AUTOSAR XML (schema 4-0-3)
standard types defined: Boolean, UInt16, UInt8
package /AUTOSAR_Platform/DataConstrs
  range DC_Boolean: raw 0..1
  range DC_UInt16: raw 0..65535
  range DC_UInt8: raw 0..255
package /PATAC/MSM/ComponentTypes
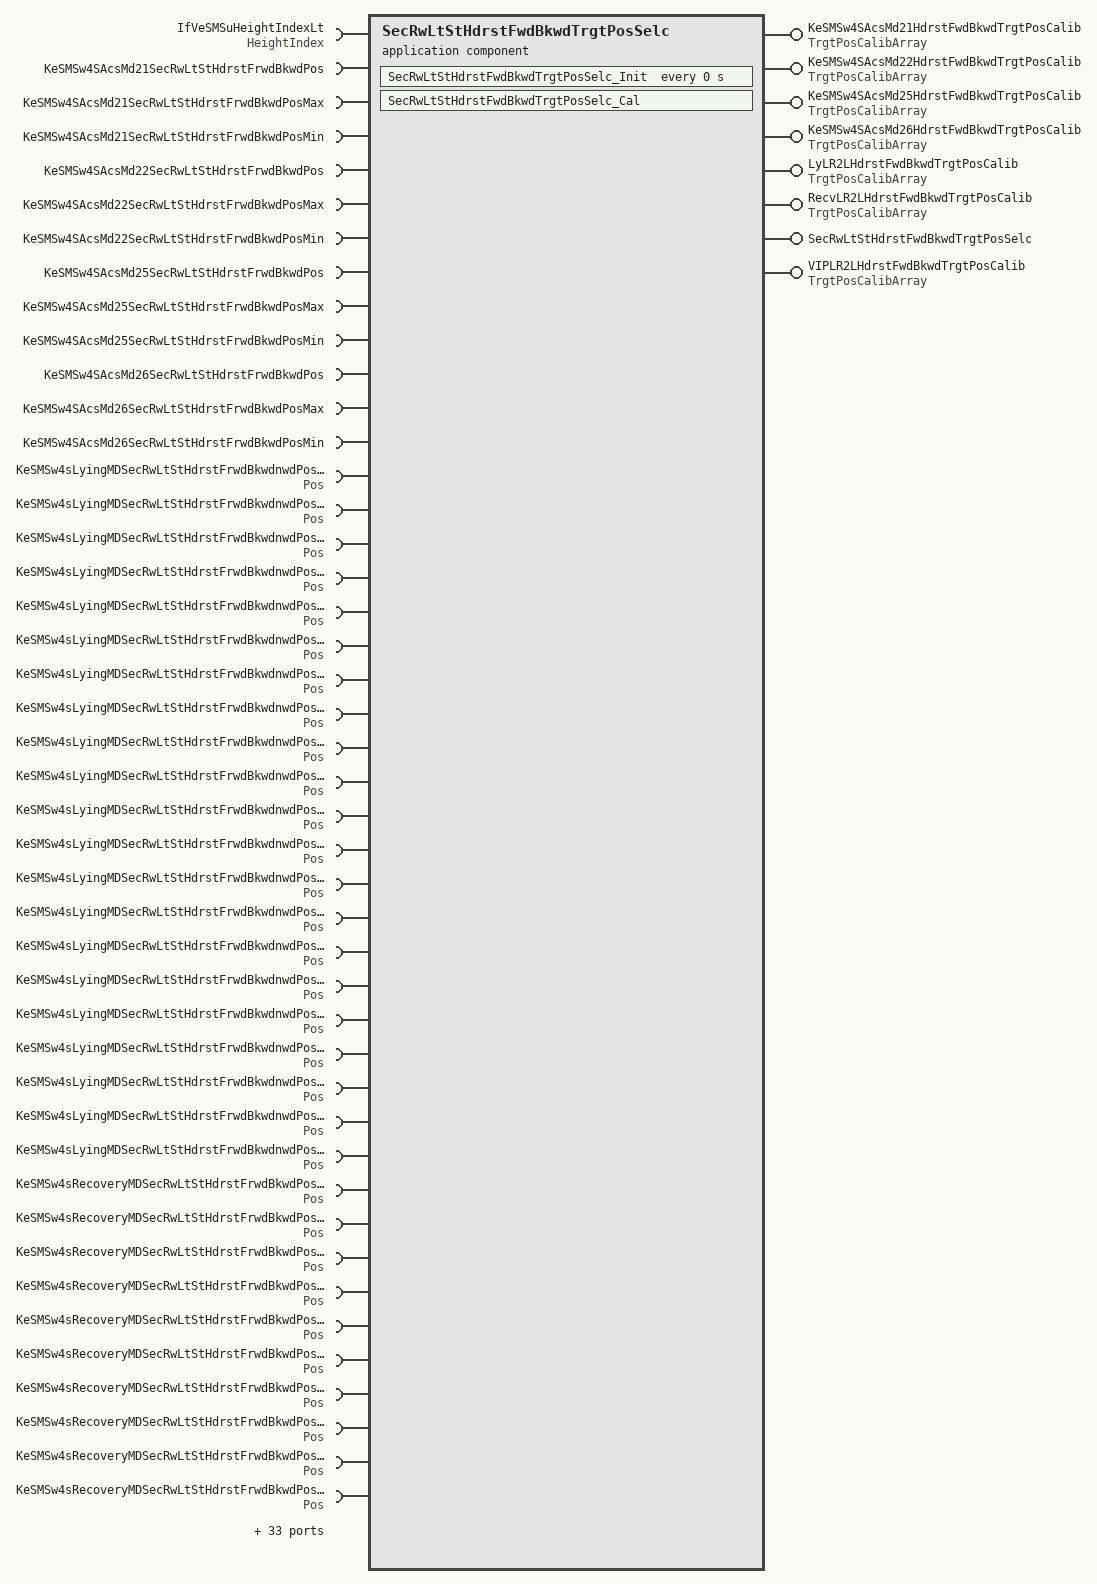
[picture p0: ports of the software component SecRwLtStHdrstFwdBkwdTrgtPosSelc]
  application sw component type SecRwLtStHdrstFwdBkwdTrgtPosSelc
    8 x provide port:
      KeSMSw4SAcsMd21HdrstFwdBkwdTrgtPosCalib: nonqueued-sender-com-spec{data-element=TrgtPosArray, init-value=[4095, 4095, 4095]}, provided-interface=TrgtPosCalibArray
      KeSMSw4SAcsMd22HdrstFwdBkwdTrgtPosCalib: nonqueued-sender-com-spec{data-element=TrgtPosArray, init-value=[4095, 4095, 4095]}, provided-interface=TrgtPosCalibArray
      KeSMSw4SAcsMd25HdrstFwdBkwdTrgtPosCalib: nonqueued-sender-com-spec{data-element=TrgtPosArray, init-value=[4095, 4095, 4095]}, provided-interface=TrgtPosCalibArray
      KeSMSw4SAcsMd26HdrstFwdBkwdTrgtPosCalib: nonqueued-sender-com-spec{data-element=TrgtPosArray, init-value=[4095, 4095, 4095]}, provided-interface=TrgtPosCalibArray
      LyLR2LHdrstFwdBkwdTrgtPosCalib: nonqueued-sender-com-spec{data-element=TrgtPosArray, init-value=[4095, 4095, 4095]}, provided-interface=TrgtPosCalibArray
      RecvLR2LHdrstFwdBkwdTrgtPosCalib: nonqueued-sender-com-spec{data-element=TrgtPosArray, init-value=[4095, 4095, 4095]}, provided-interface=TrgtPosCalibArray
      SecRwLtStHdrstFwdBkwdTrgtPosSelc: server-com-spec{operation=Cal, queue-length=1}, provided-interface=SecRwLtStHdrstFwdBkwdTrgtPosSelc
      VIPLR2LHdrstFwdBkwdTrgtPosCalib: nonqueued-sender-com-spec{data-element=TrgtPosArray, init-value=[4095, 4095, 4095]}, provided-interface=TrgtPosCalibArray
    77 x require port:
      IfVeSMSuHeightIndexLt: nonqueued-receiver-com-spec{data-element=Val, filter=data-filter-type=ALWAYS, init-value=0}, required-interface=HeightIndex
      KeSMSw4SAcsMd21SecRwLtStHdrstFrwdBkwdPos: parameter-require-com-spec{init-value=0, parameter=KeSMSw4SAcsMd21SecRwLtStHdrstFrwdBkwdPos/Val}, required-interface=KeSMSw4SAcsMd21SecRwLtStHdrstFrwdBkwdPos
      KeSMSw4SAcsMd21SecRwLtStHdrstFrwdBkwdPosMax: parameter-require-com-spec{init-value=0, parameter=KeSMSw4SAcsMd21SecRwLtStHdrstFrwdBkwdPosMax/Val}, required-interface=KeSMSw4SAcsMd21SecRwLtStHdrstFrwdBkwdPosMax
      KeSMSw4SAcsMd21SecRwLtStHdrstFrwdBkwdPosMin: parameter-require-com-spec{init-value=0, parameter=KeSMSw4SAcsMd21SecRwLtStHdrstFrwdBkwdPosMin/Val}, required-interface=KeSMSw4SAcsMd21SecRwLtStHdrstFrwdBkwdPosMin
      KeSMSw4SAcsMd22SecRwLtStHdrstFrwdBkwdPos: parameter-require-com-spec{init-value=0, parameter=KeSMSw4SAcsMd22SecRwLtStHdrstFrwdBkwdPos/Val}, required-interface=KeSMSw4SAcsMd22SecRwLtStHdrstFrwdBkwdPos
      KeSMSw4SAcsMd22SecRwLtStHdrstFrwdBkwdPosMax: parameter-require-com-spec{init-value=0, parameter=KeSMSw4SAcsMd22SecRwLtStHdrstFrwdBkwdPosMax/Val}, required-interface=KeSMSw4SAcsMd22SecRwLtStHdrstFrwdBkwdPosMax
      KeSMSw4SAcsMd22SecRwLtStHdrstFrwdBkwdPosMin: parameter-require-com-spec{init-value=0, parameter=KeSMSw4SAcsMd22SecRwLtStHdrstFrwdBkwdPosMin/Val}, required-interface=KeSMSw4SAcsMd22SecRwLtStHdrstFrwdBkwdPosMin
      KeSMSw4SAcsMd25SecRwLtStHdrstFrwdBkwdPos: parameter-require-com-spec{init-value=0, parameter=KeSMSw4SAcsMd25SecRwLtStHdrstFrwdBkwdPos/Val}, required-interface=KeSMSw4SAcsMd25SecRwLtStHdrstFrwdBkwdPos
      KeSMSw4SAcsMd25SecRwLtStHdrstFrwdBkwdPosMax: parameter-require-com-spec{init-value=0, parameter=KeSMSw4SAcsMd25SecRwLtStHdrstFrwdBkwdPosMax/Val}, required-interface=KeSMSw4SAcsMd25SecRwLtStHdrstFrwdBkwdPosMax
      KeSMSw4SAcsMd25SecRwLtStHdrstFrwdBkwdPosMin: parameter-require-com-spec{init-value=0, parameter=KeSMSw4SAcsMd25SecRwLtStHdrstFrwdBkwdPosMin/Val}, required-interface=KeSMSw4SAcsMd25SecRwLtStHdrstFrwdBkwdPosMin
      KeSMSw4SAcsMd26SecRwLtStHdrstFrwdBkwdPos: parameter-require-com-spec{init-value=0, parameter=KeSMSw4SAcsMd26SecRwLtStHdrstFrwdBkwdPos/Val}, required-interface=KeSMSw4SAcsMd26SecRwLtStHdrstFrwdBkwdPos
      KeSMSw4SAcsMd26SecRwLtStHdrstFrwdBkwdPosMax: parameter-require-com-spec{init-value=0, parameter=KeSMSw4SAcsMd26SecRwLtStHdrstFrwdBkwdPosMax/Val}, required-interface=KeSMSw4SAcsMd26SecRwLtStHdrstFrwdBkwdPosMax
      KeSMSw4SAcsMd26SecRwLtStHdrstFrwdBkwdPosMin: parameter-require-com-spec{init-value=0, parameter=KeSMSw4SAcsMd26SecRwLtStHdrstFrwdBkwdPosMin/Val}, required-interface=KeSMSw4SAcsMd26SecRwLtStHdrstFrwdBkwdPosMin
      KeSMSw4sLyingMDSecRwLtStHdrstFrwdBkwdnwdPos_160: parameter-require-com-spec{init-value=0, parameter=Pos/Val}, required-interface=Pos
      KeSMSw4sLyingMDSecRwLtStHdrstFrwdBkwdnwdPos_165: parameter-require-com-spec{init-value=0, parameter=Pos/Val}, required-interface=Pos
      KeSMSw4sLyingMDSecRwLtStHdrstFrwdBkwdnwdPos_170: parameter-require-com-spec{init-value=0, parameter=Pos/Val}, required-interface=Pos
      KeSMSw4sLyingMDSecRwLtStHdrstFrwdBkwdnwdPos_175: parameter-require-com-spec{init-value=0, parameter=Pos/Val}, required-interface=Pos
      KeSMSw4sLyingMDSecRwLtStHdrstFrwdBkwdnwdPos_180: parameter-require-com-spec{init-value=0, parameter=Pos/Val}, required-interface=Pos
      KeSMSw4sLyingMDSecRwLtStHdrstFrwdBkwdnwdPos_Below160: parameter-require-com-spec{init-value=0, parameter=Pos/Val}, required-interface=Pos
      KeSMSw4sLyingMDSecRwLtStHdrstFrwdBkwdnwdPos_Over180: parameter-require-com-spec{init-value=0, parameter=Pos/Val}, required-interface=Pos
      KeSMSw4sLyingMDSecRwLtStHdrstFrwdBkwdnwdPosMax_160: parameter-require-com-spec{init-value=0, parameter=Pos/Val}, required-interface=Pos
      KeSMSw4sLyingMDSecRwLtStHdrstFrwdBkwdnwdPosMax_165: parameter-require-com-spec{init-value=0, parameter=Pos/Val}, required-interface=Pos
      KeSMSw4sLyingMDSecRwLtStHdrstFrwdBkwdnwdPosMax_170: parameter-require-com-spec{init-value=0, parameter=Pos/Val}, required-interface=Pos
      KeSMSw4sLyingMDSecRwLtStHdrstFrwdBkwdnwdPosMax_175: parameter-require-com-spec{init-value=0, parameter=Pos/Val}, required-interface=Pos
      KeSMSw4sLyingMDSecRwLtStHdrstFrwdBkwdnwdPosMax_180: parameter-require-com-spec{init-value=0, parameter=Pos/Val}, required-interface=Pos
      KeSMSw4sLyingMDSecRwLtStHdrstFrwdBkwdnwdPosMax_Below160: parameter-require-com-spec{init-value=0, parameter=Pos/Val}, required-interface=Pos
      KeSMSw4sLyingMDSecRwLtStHdrstFrwdBkwdnwdPosMax_Over180: parameter-require-com-spec{init-value=0, parameter=Pos/Val}, required-interface=Pos
      KeSMSw4sLyingMDSecRwLtStHdrstFrwdBkwdnwdPosMin_160: parameter-require-com-spec{init-value=0, parameter=Pos/Val}, required-interface=Pos
      KeSMSw4sLyingMDSecRwLtStHdrstFrwdBkwdnwdPosMin_165: parameter-require-com-spec{init-value=0, parameter=Pos/Val}, required-interface=Pos
      KeSMSw4sLyingMDSecRwLtStHdrstFrwdBkwdnwdPosMin_170: parameter-require-com-spec{init-value=0, parameter=Pos/Val}, required-interface=Pos
      KeSMSw4sLyingMDSecRwLtStHdrstFrwdBkwdnwdPosMin_175: parameter-require-com-spec{init-value=0, parameter=Pos/Val}, required-interface=Pos
      KeSMSw4sLyingMDSecRwLtStHdrstFrwdBkwdnwdPosMin_180: parameter-require-com-spec{init-value=0, parameter=Pos/Val}, required-interface=Pos
      KeSMSw4sLyingMDSecRwLtStHdrstFrwdBkwdnwdPosMin_Below160: parameter-require-com-spec{init-value=0, parameter=Pos/Val}, required-interface=Pos
      KeSMSw4sLyingMDSecRwLtStHdrstFrwdBkwdnwdPosMin_Over180: parameter-require-com-spec{init-value=0, parameter=Pos/Val}, required-interface=Pos
      KeSMSw4sRecoveryMDSecRwLtStHdrstFrwdBkwdPos_160: parameter-require-com-spec{init-value=0, parameter=Pos/Val}, required-interface=Pos
      KeSMSw4sRecoveryMDSecRwLtStHdrstFrwdBkwdPos_165: parameter-require-com-spec{init-value=0, parameter=Pos/Val}, required-interface=Pos
      KeSMSw4sRecoveryMDSecRwLtStHdrstFrwdBkwdPos_170: parameter-require-com-spec{init-value=0, parameter=Pos/Val}, required-interface=Pos
      KeSMSw4sRecoveryMDSecRwLtStHdrstFrwdBkwdPos_175: parameter-require-com-spec{init-value=0, parameter=Pos/Val}, required-interface=Pos
      KeSMSw4sRecoveryMDSecRwLtStHdrstFrwdBkwdPos_180: parameter-require-com-spec{init-value=0, parameter=Pos/Val}, required-interface=Pos
      KeSMSw4sRecoveryMDSecRwLtStHdrstFrwdBkwdPos_Below160: parameter-require-com-spec{init-value=0, parameter=Pos/Val}, required-interface=Pos
      KeSMSw4sRecoveryMDSecRwLtStHdrstFrwdBkwdPos_Over180: parameter-require-com-spec{init-value=0, parameter=Pos/Val}, required-interface=Pos
      KeSMSw4sRecoveryMDSecRwLtStHdrstFrwdBkwdPosMax_160: parameter-require-com-spec{init-value=0, parameter=Pos/Val}, required-interface=Pos
      KeSMSw4sRecoveryMDSecRwLtStHdrstFrwdBkwdPosMax_165: parameter-require-com-spec{init-value=0, parameter=Pos/Val}, required-interface=Pos
      KeSMSw4sRecoveryMDSecRwLtStHdrstFrwdBkwdPosMax_170: parameter-require-com-spec{init-value=0, parameter=Pos/Val}, required-interface=Pos
      KeSMSw4sRecoveryMDSecRwLtStHdrstFrwdBkwdPosMax_175: parameter-require-com-spec{init-value=0, parameter=Pos/Val}, required-interface=Pos
      KeSMSw4sRecoveryMDSecRwLtStHdrstFrwdBkwdPosMax_180: parameter-require-com-spec{init-value=0, parameter=Pos/Val}, required-interface=Pos
      KeSMSw4sRecoveryMDSecRwLtStHdrstFrwdBkwdPosMax_Below160: parameter-require-com-spec{init-value=0, parameter=Pos/Val}, required-interface=Pos
      KeSMSw4sRecoveryMDSecRwLtStHdrstFrwdBkwdPosMax_Over180: parameter-require-com-spec{init-value=0, parameter=Pos/Val}, required-interface=Pos
      KeSMSw4sRecoveryMDSecRwLtStHdrstFrwdBkwdPosMin_160: parameter-require-com-spec{init-value=0, parameter=Pos/Val}, required-interface=Pos
      KeSMSw4sRecoveryMDSecRwLtStHdrstFrwdBkwdPosMin_165: parameter-require-com-spec{init-value=0, parameter=Pos/Val}, required-interface=Pos
      KeSMSw4sRecoveryMDSecRwLtStHdrstFrwdBkwdPosMin_170: parameter-require-com-spec{init-value=0, parameter=Pos/Val}, required-interface=Pos
      KeSMSw4sRecoveryMDSecRwLtStHdrstFrwdBkwdPosMin_175: parameter-require-com-spec{init-value=0, parameter=Pos/Val}, required-interface=Pos
      KeSMSw4sRecoveryMDSecRwLtStHdrstFrwdBkwdPosMin_180: parameter-require-com-spec{init-value=0, parameter=Pos/Val}, required-interface=Pos
      KeSMSw4sRecoveryMDSecRwLtStHdrstFrwdBkwdPosMin_Below160: parameter-require-com-spec{init-value=0, parameter=Pos/Val}, required-interface=Pos
      KeSMSw4sRecoveryMDSecRwLtStHdrstFrwdBkwdPosMin_Over180: parameter-require-com-spec{init-value=0, parameter=Pos/Val}, required-interface=Pos
      KeSMSw4sVIPMDSecRwLtStHdrstFrwdBkwdPos_160: parameter-require-com-spec{init-value=0, parameter=Pos/Val}, required-interface=Pos
      KeSMSw4sVIPMDSecRwLtStHdrstFrwdBkwdPos_165: parameter-require-com-spec{init-value=0, parameter=Pos/Val}, required-interface=Pos
      KeSMSw4sVIPMDSecRwLtStHdrstFrwdBkwdPos_170: parameter-require-com-spec{init-value=0, parameter=Pos/Val}, required-interface=Pos
      KeSMSw4sVIPMDSecRwLtStHdrstFrwdBkwdPos_175: parameter-require-com-spec{init-value=0, parameter=Pos/Val}, required-interface=Pos
      KeSMSw4sVIPMDSecRwLtStHdrstFrwdBkwdPos_180: parameter-require-com-spec{init-value=0, parameter=Pos/Val}, required-interface=Pos
      KeSMSw4sVIPMDSecRwLtStHdrstFrwdBkwdPos_Below160: parameter-require-com-spec{init-value=0, parameter=Pos/Val}, required-interface=Pos
      KeSMSw4sVIPMDSecRwLtStHdrstFrwdBkwdPos_Over180: parameter-require-com-spec{init-value=0, parameter=Pos/Val}, required-interface=Pos
      KeSMSw4sVIPMDSecRwLtStHdrstFrwdBkwdPosMax_160: parameter-require-com-spec{init-value=0, parameter=Pos/Val}, required-interface=Pos
      KeSMSw4sVIPMDSecRwLtStHdrstFrwdBkwdPosMax_165: parameter-require-com-spec{init-value=0, parameter=Pos/Val}, required-interface=Pos
      KeSMSw4sVIPMDSecRwLtStHdrstFrwdBkwdPosMax_170: parameter-require-com-spec{init-value=0, parameter=Pos/Val}, required-interface=Pos
      KeSMSw4sVIPMDSecRwLtStHdrstFrwdBkwdPosMax_175: parameter-require-com-spec{init-value=0, parameter=Pos/Val}, required-interface=Pos
      KeSMSw4sVIPMDSecRwLtStHdrstFrwdBkwdPosMax_180: parameter-require-com-spec{init-value=0, parameter=Pos/Val}, required-interface=Pos
      KeSMSw4sVIPMDSecRwLtStHdrstFrwdBkwdPosMax_Below160: parameter-require-com-spec{init-value=0, parameter=Pos/Val}, required-interface=Pos
      KeSMSw4sVIPMDSecRwLtStHdrstFrwdBkwdPosMax_Over180: parameter-require-com-spec{init-value=0, parameter=Pos/Val}, required-interface=Pos
      KeSMSw4sVIPMDSecRwLtStHdrstFrwdBkwdPosMin_160: parameter-require-com-spec{init-value=0, parameter=Pos/Val}, required-interface=Pos
      KeSMSw4sVIPMDSecRwLtStHdrstFrwdBkwdPosMin_165: parameter-require-com-spec{init-value=0, parameter=Pos/Val}, required-interface=Pos
      KeSMSw4sVIPMDSecRwLtStHdrstFrwdBkwdPosMin_170: parameter-require-com-spec{init-value=0, parameter=Pos/Val}, required-interface=Pos
      KeSMSw4sVIPMDSecRwLtStHdrstFrwdBkwdPosMin_175: parameter-require-com-spec{init-value=0, parameter=Pos/Val}, required-interface=Pos
      KeSMSw4sVIPMDSecRwLtStHdrstFrwdBkwdPosMin_180: parameter-require-com-spec{init-value=0, parameter=Pos/Val}, required-interface=Pos
      KeSMSw4sVIPMDSecRwLtStHdrstFrwdBkwdPosMin_Below160: parameter-require-com-spec{init-value=0, parameter=Pos/Val}, required-interface=Pos
      KeSMSw4sVIPMDSecRwLtStHdrstFrwdBkwdPosMin_Over180: parameter-require-com-spec{init-value=0, parameter=Pos/Val}, required-interface=Pos
      StNumFlg: required-interface=StNumFlg
        required-com-specs:
          data-element=Is4s, filter=data-filter-type=ALWAYS, init-value=0
          data-element=Is6s, filter=data-filter-type=ALWAYS, init-value=0
          data-element=Is6s7s, filter=data-filter-type=ALWAYS, init-value=0
          data-element=Is7s, filter=data-filter-type=ALWAYS, init-value=0
    behavior SecRwLtStHdrstFwdBkwdTrgtPosSelc_InternalBehavior
      operation invoked event OIT_SecRwLtStHdrstFwdBkwdTrgtPosSelc_Cal_SecRwLtStHdrstFwdBkwdTrgtPosSelc_Cal: start-on-event=SecRwLtStHdrstFwdBkwdTrgtPosSelc_Cal, operation=SecRwLtStHdrstFwdBkwdTrgtPosSelc.Cal
      timing event SecRwLtStHdrstFwdBkwdTrgtPosSelc_InitEvent: start-on-event=SecRwLtStHdrstFwdBkwdTrgtPosSelc_Init, period=0
      runnable SecRwLtStHdrstFwdBkwdTrgtPosSelc_Cal
        data-receive-point-by-arguments:
          5 x access:
            REC_IfVeSMSuHeightIndexLt_Val: accessed-variable=IfVeSMSuHeightIndexLt.Val
            REC_StNumFlg_Is4s: accessed-variable=StNumFlg.Is4s
            REC_StNumFlg_Is6s: accessed-variable=StNumFlg.Is6s
            REC_StNumFlg_Is6s7s: accessed-variable=StNumFlg.Is6s7s
            REC_StNumFlg_Is7s: accessed-variable=StNumFlg.Is7s
        data-send-points:
          7 x access:
            SEND_KeSMSw4SAcsMd21HdrstFwdBkwdTrgtPosCalib_TrgtPosArray: accessed-variable=KeSMSw4SAcsMd21HdrstFwdBkwdTrgtPosCalib.TrgtPosArray
            SEND_KeSMSw4SAcsMd22HdrstFwdBkwdTrgtPosCalib_TrgtPosArray: accessed-variable=KeSMSw4SAcsMd22HdrstFwdBkwdTrgtPosCalib.TrgtPosArray
            SEND_KeSMSw4SAcsMd25HdrstFwdBkwdTrgtPosCalib_TrgtPosArray: accessed-variable=KeSMSw4SAcsMd25HdrstFwdBkwdTrgtPosCalib.TrgtPosArray
            SEND_KeSMSw4SAcsMd26HdrstFwdBkwdTrgtPosCalib_TrgtPosArray: accessed-variable=KeSMSw4SAcsMd26HdrstFwdBkwdTrgtPosCalib.TrgtPosArray
            SEND_LyLR2LHdrstFwdBkwdTrgtPosCalib_TrgtPosArray: accessed-variable=LyLR2LHdrstFwdBkwdTrgtPosCalib.TrgtPosArray
            SEND_RecvLR2LHdrstFwdBkwdTrgtPosCalib_TrgtPosArray: accessed-variable=RecvLR2LHdrstFwdBkwdTrgtPosCalib.TrgtPosArray
            SEND_VIPLR2LHdrstFwdBkwdTrgtPosCalib_TrgtPosArray: accessed-variable=VIPLR2LHdrstFwdBkwdTrgtPosCalib.TrgtPosArray
        75 x parameter access:
          PA_KeSMSw4SAcsMd21SecRwLtStHdrstFrwdBkwdPos_Val: accessed-parameter=KeSMSw4SAcsMd21SecRwLtStHdrstFrwdBkwdPos.Val
          PA_KeSMSw4SAcsMd21SecRwLtStHdrstFrwdBkwdPosMax_Val: accessed-parameter=KeSMSw4SAcsMd21SecRwLtStHdrstFrwdBkwdPosMax.Val
          PA_KeSMSw4SAcsMd21SecRwLtStHdrstFrwdBkwdPosMin_Val: accessed-parameter=KeSMSw4SAcsMd21SecRwLtStHdrstFrwdBkwdPosMin.Val
          PA_KeSMSw4SAcsMd22SecRwLtStHdrstFrwdBkwdPos_Val: accessed-parameter=KeSMSw4SAcsMd22SecRwLtStHdrstFrwdBkwdPos.Val
          PA_KeSMSw4SAcsMd22SecRwLtStHdrstFrwdBkwdPosMax_Val: accessed-parameter=KeSMSw4SAcsMd22SecRwLtStHdrstFrwdBkwdPosMax.Val
          PA_KeSMSw4SAcsMd22SecRwLtStHdrstFrwdBkwdPosMin_Val: accessed-parameter=KeSMSw4SAcsMd22SecRwLtStHdrstFrwdBkwdPosMin.Val
          PA_KeSMSw4SAcsMd25SecRwLtStHdrstFrwdBkwdPos_Val: accessed-parameter=KeSMSw4SAcsMd25SecRwLtStHdrstFrwdBkwdPos.Val
          PA_KeSMSw4SAcsMd25SecRwLtStHdrstFrwdBkwdPosMax_Val: accessed-parameter=KeSMSw4SAcsMd25SecRwLtStHdrstFrwdBkwdPosMax.Val
          PA_KeSMSw4SAcsMd25SecRwLtStHdrstFrwdBkwdPosMin_Val: accessed-parameter=KeSMSw4SAcsMd25SecRwLtStHdrstFrwdBkwdPosMin.Val
          PA_KeSMSw4SAcsMd26SecRwLtStHdrstFrwdBkwdPos_Val: accessed-parameter=KeSMSw4SAcsMd26SecRwLtStHdrstFrwdBkwdPos.Val
          PA_KeSMSw4SAcsMd26SecRwLtStHdrstFrwdBkwdPosMax_Val: accessed-parameter=KeSMSw4SAcsMd26SecRwLtStHdrstFrwdBkwdPosMax.Val
          PA_KeSMSw4SAcsMd26SecRwLtStHdrstFrwdBkwdPosMin_Val: accessed-parameter=KeSMSw4SAcsMd26SecRwLtStHdrstFrwdBkwdPosMin.Val
          PA_KeSMSw4sLyingMDSecRwLtStHdrstFrwdBkwdnwdPos_160_Val: accessed-parameter=KeSMSw4sLyingMDSecRwLtStHdrstFrwdBkwdnwdPos_160.Val
          PA_KeSMSw4sLyingMDSecRwLtStHdrstFrwdBkwdnwdPos_165_Val: accessed-parameter=KeSMSw4sLyingMDSecRwLtStHdrstFrwdBkwdnwdPos_165.Val
          PA_KeSMSw4sLyingMDSecRwLtStHdrstFrwdBkwdnwdPos_170_Val: accessed-parameter=KeSMSw4sLyingMDSecRwLtStHdrstFrwdBkwdnwdPos_170.Val
          PA_KeSMSw4sLyingMDSecRwLtStHdrstFrwdBkwdnwdPos_175_Val: accessed-parameter=KeSMSw4sLyingMDSecRwLtStHdrstFrwdBkwdnwdPos_175.Val
          PA_KeSMSw4sLyingMDSecRwLtStHdrstFrwdBkwdnwdPos_180_Val: accessed-parameter=KeSMSw4sLyingMDSecRwLtStHdrstFrwdBkwdnwdPos_180.Val
          PA_KeSMSw4sLyingMDSecRwLtStHdrstFrwdBkwdnwdPos_Below160_Val: accessed-parameter=KeSMSw4sLyingMDSecRwLtStHdrstFrwdBkwdnwdPos_Below160.Val
          PA_KeSMSw4sLyingMDSecRwLtStHdrstFrwdBkwdnwdPos_Over180_Val: accessed-parameter=KeSMSw4sLyingMDSecRwLtStHdrstFrwdBkwdnwdPos_Over180.Val
          PA_KeSMSw4sLyingMDSecRwLtStHdrstFrwdBkwdnwdPosMax_160_Val: accessed-parameter=KeSMSw4sLyingMDSecRwLtStHdrstFrwdBkwdnwdPosMax_160.Val
          PA_KeSMSw4sLyingMDSecRwLtStHdrstFrwdBkwdnwdPosMax_165_Val: accessed-parameter=KeSMSw4sLyingMDSecRwLtStHdrstFrwdBkwdnwdPosMax_165.Val
          PA_KeSMSw4sLyingMDSecRwLtStHdrstFrwdBkwdnwdPosMax_170_Val: accessed-parameter=KeSMSw4sLyingMDSecRwLtStHdrstFrwdBkwdnwdPosMax_170.Val
          PA_KeSMSw4sLyingMDSecRwLtStHdrstFrwdBkwdnwdPosMax_175_Val: accessed-parameter=KeSMSw4sLyingMDSecRwLtStHdrstFrwdBkwdnwdPosMax_175.Val
          PA_KeSMSw4sLyingMDSecRwLtStHdrstFrwdBkwdnwdPosMax_180_Val: accessed-parameter=KeSMSw4sLyingMDSecRwLtStHdrstFrwdBkwdnwdPosMax_180.Val
          PA_KeSMSw4sLyingMDSecRwLtStHdrstFrwdBkwdnwdPosMax_Below160_Val: accessed-parameter=KeSMSw4sLyingMDSecRwLtStHdrstFrwdBkwdnwdPosMax_Below160.Val
          PA_KeSMSw4sLyingMDSecRwLtStHdrstFrwdBkwdnwdPosMax_Over180_Val: accessed-parameter=KeSMSw4sLyingMDSecRwLtStHdrstFrwdBkwdnwdPosMax_Over180.Val
          PA_KeSMSw4sLyingMDSecRwLtStHdrstFrwdBkwdnwdPosMin_160_Val: accessed-parameter=KeSMSw4sLyingMDSecRwLtStHdrstFrwdBkwdnwdPosMin_160.Val
          PA_KeSMSw4sLyingMDSecRwLtStHdrstFrwdBkwdnwdPosMin_165_Val: accessed-parameter=KeSMSw4sLyingMDSecRwLtStHdrstFrwdBkwdnwdPosMin_165.Val
          PA_KeSMSw4sLyingMDSecRwLtStHdrstFrwdBkwdnwdPosMin_170_Val: accessed-parameter=KeSMSw4sLyingMDSecRwLtStHdrstFrwdBkwdnwdPosMin_170.Val
          PA_KeSMSw4sLyingMDSecRwLtStHdrstFrwdBkwdnwdPosMin_175_Val: accessed-parameter=KeSMSw4sLyingMDSecRwLtStHdrstFrwdBkwdnwdPosMin_175.Val
          PA_KeSMSw4sLyingMDSecRwLtStHdrstFrwdBkwdnwdPosMin_180_Val: accessed-parameter=KeSMSw4sLyingMDSecRwLtStHdrstFrwdBkwdnwdPosMin_180.Val
          PA_KeSMSw4sLyingMDSecRwLtStHdrstFrwdBkwdnwdPosMin_Below160_Val: accessed-parameter=KeSMSw4sLyingMDSecRwLtStHdrstFrwdBkwdnwdPosMin_Below160.Val
          PA_KeSMSw4sLyingMDSecRwLtStHdrstFrwdBkwdnwdPosMin_Over180_Val: accessed-parameter=KeSMSw4sLyingMDSecRwLtStHdrstFrwdBkwdnwdPosMin_Over180.Val
          PA_KeSMSw4sRecoveryMDSecRwLtStHdrstFrwdBkwdPos_160_Val: accessed-parameter=KeSMSw4sRecoveryMDSecRwLtStHdrstFrwdBkwdPos_160.Val
          PA_KeSMSw4sRecoveryMDSecRwLtStHdrstFrwdBkwdPos_165_Val: accessed-parameter=KeSMSw4sRecoveryMDSecRwLtStHdrstFrwdBkwdPos_165.Val
          PA_KeSMSw4sRecoveryMDSecRwLtStHdrstFrwdBkwdPos_170_Val: accessed-parameter=KeSMSw4sRecoveryMDSecRwLtStHdrstFrwdBkwdPos_170.Val
          PA_KeSMSw4sRecoveryMDSecRwLtStHdrstFrwdBkwdPos_175_Val: accessed-parameter=KeSMSw4sRecoveryMDSecRwLtStHdrstFrwdBkwdPos_175.Val
          PA_KeSMSw4sRecoveryMDSecRwLtStHdrstFrwdBkwdPos_180_Val: accessed-parameter=KeSMSw4sRecoveryMDSecRwLtStHdrstFrwdBkwdPos_180.Val
          PA_KeSMSw4sRecoveryMDSecRwLtStHdrstFrwdBkwdPos_Below160_Val: accessed-parameter=KeSMSw4sRecoveryMDSecRwLtStHdrstFrwdBkwdPos_Below160.Val
          PA_KeSMSw4sRecoveryMDSecRwLtStHdrstFrwdBkwdPos_Over180_Val: accessed-parameter=KeSMSw4sRecoveryMDSecRwLtStHdrstFrwdBkwdPos_Over180.Val
          PA_KeSMSw4sRecoveryMDSecRwLtStHdrstFrwdBkwdPosMax_160_Val: accessed-parameter=KeSMSw4sRecoveryMDSecRwLtStHdrstFrwdBkwdPosMax_160.Val
          PA_KeSMSw4sRecoveryMDSecRwLtStHdrstFrwdBkwdPosMax_165_Val: accessed-parameter=KeSMSw4sRecoveryMDSecRwLtStHdrstFrwdBkwdPosMax_165.Val
          PA_KeSMSw4sRecoveryMDSecRwLtStHdrstFrwdBkwdPosMax_170_Val: accessed-parameter=KeSMSw4sRecoveryMDSecRwLtStHdrstFrwdBkwdPosMax_170.Val
          PA_KeSMSw4sRecoveryMDSecRwLtStHdrstFrwdBkwdPosMax_175_Val: accessed-parameter=KeSMSw4sRecoveryMDSecRwLtStHdrstFrwdBkwdPosMax_175.Val
          PA_KeSMSw4sRecoveryMDSecRwLtStHdrstFrwdBkwdPosMax_180_Val: accessed-parameter=KeSMSw4sRecoveryMDSecRwLtStHdrstFrwdBkwdPosMax_180.Val
          PA_KeSMSw4sRecoveryMDSecRwLtStHdrstFrwdBkwdPosMax_Below160_Val: accessed-parameter=KeSMSw4sRecoveryMDSecRwLtStHdrstFrwdBkwdPosMax_Below160.Val
          PA_KeSMSw4sRecoveryMDSecRwLtStHdrstFrwdBkwdPosMax_Over180_Val: accessed-parameter=KeSMSw4sRecoveryMDSecRwLtStHdrstFrwdBkwdPosMax_Over180.Val
          PA_KeSMSw4sRecoveryMDSecRwLtStHdrstFrwdBkwdPosMin_160_Val: accessed-parameter=KeSMSw4sRecoveryMDSecRwLtStHdrstFrwdBkwdPosMin_160.Val
          PA_KeSMSw4sRecoveryMDSecRwLtStHdrstFrwdBkwdPosMin_165_Val: accessed-parameter=KeSMSw4sRecoveryMDSecRwLtStHdrstFrwdBkwdPosMin_165.Val
          PA_KeSMSw4sRecoveryMDSecRwLtStHdrstFrwdBkwdPosMin_170_Val: accessed-parameter=KeSMSw4sRecoveryMDSecRwLtStHdrstFrwdBkwdPosMin_170.Val
          PA_KeSMSw4sRecoveryMDSecRwLtStHdrstFrwdBkwdPosMin_175_Val: accessed-parameter=KeSMSw4sRecoveryMDSecRwLtStHdrstFrwdBkwdPosMin_175.Val
          PA_KeSMSw4sRecoveryMDSecRwLtStHdrstFrwdBkwdPosMin_180_Val: accessed-parameter=KeSMSw4sRecoveryMDSecRwLtStHdrstFrwdBkwdPosMin_180.Val
          PA_KeSMSw4sRecoveryMDSecRwLtStHdrstFrwdBkwdPosMin_Below160_Val: accessed-parameter=KeSMSw4sRecoveryMDSecRwLtStHdrstFrwdBkwdPosMin_Below160.Val
          PA_KeSMSw4sRecoveryMDSecRwLtStHdrstFrwdBkwdPosMin_Over180_Val: accessed-parameter=KeSMSw4sRecoveryMDSecRwLtStHdrstFrwdBkwdPosMin_Over180.Val
          PA_KeSMSw4sVIPMDSecRwLtStHdrstFrwdBkwdPos_160_Val: accessed-parameter=KeSMSw4sVIPMDSecRwLtStHdrstFrwdBkwdPos_160.Val
          PA_KeSMSw4sVIPMDSecRwLtStHdrstFrwdBkwdPos_165_Val: accessed-parameter=KeSMSw4sVIPMDSecRwLtStHdrstFrwdBkwdPos_165.Val
          PA_KeSMSw4sVIPMDSecRwLtStHdrstFrwdBkwdPos_170_Val: accessed-parameter=KeSMSw4sVIPMDSecRwLtStHdrstFrwdBkwdPos_170.Val
          PA_KeSMSw4sVIPMDSecRwLtStHdrstFrwdBkwdPos_175_Val: accessed-parameter=KeSMSw4sVIPMDSecRwLtStHdrstFrwdBkwdPos_175.Val
          PA_KeSMSw4sVIPMDSecRwLtStHdrstFrwdBkwdPos_180_Val: accessed-parameter=KeSMSw4sVIPMDSecRwLtStHdrstFrwdBkwdPos_180.Val
          PA_KeSMSw4sVIPMDSecRwLtStHdrstFrwdBkwdPos_Below160_Val: accessed-parameter=KeSMSw4sVIPMDSecRwLtStHdrstFrwdBkwdPos_Below160.Val
          PA_KeSMSw4sVIPMDSecRwLtStHdrstFrwdBkwdPos_Over180_Val: accessed-parameter=KeSMSw4sVIPMDSecRwLtStHdrstFrwdBkwdPos_Over180.Val
          PA_KeSMSw4sVIPMDSecRwLtStHdrstFrwdBkwdPosMax_160_Val: accessed-parameter=KeSMSw4sVIPMDSecRwLtStHdrstFrwdBkwdPosMax_160.Val
          PA_KeSMSw4sVIPMDSecRwLtStHdrstFrwdBkwdPosMax_165_Val: accessed-parameter=KeSMSw4sVIPMDSecRwLtStHdrstFrwdBkwdPosMax_165.Val
          PA_KeSMSw4sVIPMDSecRwLtStHdrstFrwdBkwdPosMax_170_Val: accessed-parameter=KeSMSw4sVIPMDSecRwLtStHdrstFrwdBkwdPosMax_170.Val
          PA_KeSMSw4sVIPMDSecRwLtStHdrstFrwdBkwdPosMax_175_Val: accessed-parameter=KeSMSw4sVIPMDSecRwLtStHdrstFrwdBkwdPosMax_175.Val
          PA_KeSMSw4sVIPMDSecRwLtStHdrstFrwdBkwdPosMax_180_Val: accessed-parameter=KeSMSw4sVIPMDSecRwLtStHdrstFrwdBkwdPosMax_180.Val
          PA_KeSMSw4sVIPMDSecRwLtStHdrstFrwdBkwdPosMax_Below160_Val: accessed-parameter=KeSMSw4sVIPMDSecRwLtStHdrstFrwdBkwdPosMax_Below160.Val
          PA_KeSMSw4sVIPMDSecRwLtStHdrstFrwdBkwdPosMax_Over180_Val: accessed-parameter=KeSMSw4sVIPMDSecRwLtStHdrstFrwdBkwdPosMax_Over180.Val
          PA_KeSMSw4sVIPMDSecRwLtStHdrstFrwdBkwdPosMin_160_Val: accessed-parameter=KeSMSw4sVIPMDSecRwLtStHdrstFrwdBkwdPosMin_160.Val
          PA_KeSMSw4sVIPMDSecRwLtStHdrstFrwdBkwdPosMin_165_Val: accessed-parameter=KeSMSw4sVIPMDSecRwLtStHdrstFrwdBkwdPosMin_165.Val
          PA_KeSMSw4sVIPMDSecRwLtStHdrstFrwdBkwdPosMin_170_Val: accessed-parameter=KeSMSw4sVIPMDSecRwLtStHdrstFrwdBkwdPosMin_170.Val
          PA_KeSMSw4sVIPMDSecRwLtStHdrstFrwdBkwdPosMin_175_Val: accessed-parameter=KeSMSw4sVIPMDSecRwLtStHdrstFrwdBkwdPosMin_175.Val
          PA_KeSMSw4sVIPMDSecRwLtStHdrstFrwdBkwdPosMin_180_Val: accessed-parameter=KeSMSw4sVIPMDSecRwLtStHdrstFrwdBkwdPosMin_180.Val
          PA_KeSMSw4sVIPMDSecRwLtStHdrstFrwdBkwdPosMin_Below160_Val: accessed-parameter=KeSMSw4sVIPMDSecRwLtStHdrstFrwdBkwdPosMin_Below160.Val
          PA_KeSMSw4sVIPMDSecRwLtStHdrstFrwdBkwdPosMin_Over180_Val: accessed-parameter=KeSMSw4sVIPMDSecRwLtStHdrstFrwdBkwdPosMin_Over180.Val
      runnable SecRwLtStHdrstFwdBkwdTrgtPosSelc_Init
        75 x parameter access:
          PA_KeSMSw4SAcsMd21SecRwLtStHdrstFrwdBkwdPos_Val: accessed-parameter=KeSMSw4SAcsMd21SecRwLtStHdrstFrwdBkwdPos.Val
          PA_KeSMSw4SAcsMd21SecRwLtStHdrstFrwdBkwdPosMax_Val: accessed-parameter=KeSMSw4SAcsMd21SecRwLtStHdrstFrwdBkwdPosMax.Val
          PA_KeSMSw4SAcsMd21SecRwLtStHdrstFrwdBkwdPosMin_Val: accessed-parameter=KeSMSw4SAcsMd21SecRwLtStHdrstFrwdBkwdPosMin.Val
          PA_KeSMSw4SAcsMd22SecRwLtStHdrstFrwdBkwdPos_Val: accessed-parameter=KeSMSw4SAcsMd22SecRwLtStHdrstFrwdBkwdPos.Val
          PA_KeSMSw4SAcsMd22SecRwLtStHdrstFrwdBkwdPosMax_Val: accessed-parameter=KeSMSw4SAcsMd22SecRwLtStHdrstFrwdBkwdPosMax.Val
          PA_KeSMSw4SAcsMd22SecRwLtStHdrstFrwdBkwdPosMin_Val: accessed-parameter=KeSMSw4SAcsMd22SecRwLtStHdrstFrwdBkwdPosMin.Val
          PA_KeSMSw4SAcsMd25SecRwLtStHdrstFrwdBkwdPos_Val: accessed-parameter=KeSMSw4SAcsMd25SecRwLtStHdrstFrwdBkwdPos.Val
          PA_KeSMSw4SAcsMd25SecRwLtStHdrstFrwdBkwdPosMax_Val: accessed-parameter=KeSMSw4SAcsMd25SecRwLtStHdrstFrwdBkwdPosMax.Val
          PA_KeSMSw4SAcsMd25SecRwLtStHdrstFrwdBkwdPosMin_Val: accessed-parameter=KeSMSw4SAcsMd25SecRwLtStHdrstFrwdBkwdPosMin.Val
          PA_KeSMSw4SAcsMd26SecRwLtStHdrstFrwdBkwdPos_Val: accessed-parameter=KeSMSw4SAcsMd26SecRwLtStHdrstFrwdBkwdPos.Val
          PA_KeSMSw4SAcsMd26SecRwLtStHdrstFrwdBkwdPosMax_Val: accessed-parameter=KeSMSw4SAcsMd26SecRwLtStHdrstFrwdBkwdPosMax.Val
          PA_KeSMSw4SAcsMd26SecRwLtStHdrstFrwdBkwdPosMin_Val: accessed-parameter=KeSMSw4SAcsMd26SecRwLtStHdrstFrwdBkwdPosMin.Val
          PA_KeSMSw4sLyingMDSecRwLtStHdrstFrwdBkwdnwdPos_160_Val: accessed-parameter=KeSMSw4sLyingMDSecRwLtStHdrstFrwdBkwdnwdPos_160.Val
          PA_KeSMSw4sLyingMDSecRwLtStHdrstFrwdBkwdnwdPos_165_Val: accessed-parameter=KeSMSw4sLyingMDSecRwLtStHdrstFrwdBkwdnwdPos_165.Val
          PA_KeSMSw4sLyingMDSecRwLtStHdrstFrwdBkwdnwdPos_170_Val: accessed-parameter=KeSMSw4sLyingMDSecRwLtStHdrstFrwdBkwdnwdPos_170.Val
          PA_KeSMSw4sLyingMDSecRwLtStHdrstFrwdBkwdnwdPos_175_Val: accessed-parameter=KeSMSw4sLyingMDSecRwLtStHdrstFrwdBkwdnwdPos_175.Val
          PA_KeSMSw4sLyingMDSecRwLtStHdrstFrwdBkwdnwdPos_180_Val: accessed-parameter=KeSMSw4sLyingMDSecRwLtStHdrstFrwdBkwdnwdPos_180.Val
          PA_KeSMSw4sLyingMDSecRwLtStHdrstFrwdBkwdnwdPos_Below160_Val: accessed-parameter=KeSMSw4sLyingMDSecRwLtStHdrstFrwdBkwdnwdPos_Below160.Val
          PA_KeSMSw4sLyingMDSecRwLtStHdrstFrwdBkwdnwdPos_Over180_Val: accessed-parameter=KeSMSw4sLyingMDSecRwLtStHdrstFrwdBkwdnwdPos_Over180.Val
          PA_KeSMSw4sLyingMDSecRwLtStHdrstFrwdBkwdnwdPosMax_160_Val: accessed-parameter=KeSMSw4sLyingMDSecRwLtStHdrstFrwdBkwdnwdPosMax_160.Val
          PA_KeSMSw4sLyingMDSecRwLtStHdrstFrwdBkwdnwdPosMax_165_Val: accessed-parameter=KeSMSw4sLyingMDSecRwLtStHdrstFrwdBkwdnwdPosMax_165.Val
          PA_KeSMSw4sLyingMDSecRwLtStHdrstFrwdBkwdnwdPosMax_170_Val: accessed-parameter=KeSMSw4sLyingMDSecRwLtStHdrstFrwdBkwdnwdPosMax_170.Val
          PA_KeSMSw4sLyingMDSecRwLtStHdrstFrwdBkwdnwdPosMax_175_Val: accessed-parameter=KeSMSw4sLyingMDSecRwLtStHdrstFrwdBkwdnwdPosMax_175.Val
          PA_KeSMSw4sLyingMDSecRwLtStHdrstFrwdBkwdnwdPosMax_180_Val: accessed-parameter=KeSMSw4sLyingMDSecRwLtStHdrstFrwdBkwdnwdPosMax_180.Val
          PA_KeSMSw4sLyingMDSecRwLtStHdrstFrwdBkwdnwdPosMax_Below160_Val: accessed-parameter=KeSMSw4sLyingMDSecRwLtStHdrstFrwdBkwdnwdPosMax_Below160.Val
          PA_KeSMSw4sLyingMDSecRwLtStHdrstFrwdBkwdnwdPosMax_Over180_Val: accessed-parameter=KeSMSw4sLyingMDSecRwLtStHdrstFrwdBkwdnwdPosMax_Over180.Val
          PA_KeSMSw4sLyingMDSecRwLtStHdrstFrwdBkwdnwdPosMin_160_Val: accessed-parameter=KeSMSw4sLyingMDSecRwLtStHdrstFrwdBkwdnwdPosMin_160.Val
          PA_KeSMSw4sLyingMDSecRwLtStHdrstFrwdBkwdnwdPosMin_165_Val: accessed-parameter=KeSMSw4sLyingMDSecRwLtStHdrstFrwdBkwdnwdPosMin_165.Val
          PA_KeSMSw4sLyingMDSecRwLtStHdrstFrwdBkwdnwdPosMin_170_Val: accessed-parameter=KeSMSw4sLyingMDSecRwLtStHdrstFrwdBkwdnwdPosMin_170.Val
          PA_KeSMSw4sLyingMDSecRwLtStHdrstFrwdBkwdnwdPosMin_175_Val: accessed-parameter=KeSMSw4sLyingMDSecRwLtStHdrstFrwdBkwdnwdPosMin_175.Val
          PA_KeSMSw4sLyingMDSecRwLtStHdrstFrwdBkwdnwdPosMin_180_Val: accessed-parameter=KeSMSw4sLyingMDSecRwLtStHdrstFrwdBkwdnwdPosMin_180.Val
          PA_KeSMSw4sLyingMDSecRwLtStHdrstFrwdBkwdnwdPosMin_Below160_Val: accessed-parameter=KeSMSw4sLyingMDSecRwLtStHdrstFrwdBkwdnwdPosMin_Below160.Val
          PA_KeSMSw4sLyingMDSecRwLtStHdrstFrwdBkwdnwdPosMin_Over180_Val: accessed-parameter=KeSMSw4sLyingMDSecRwLtStHdrstFrwdBkwdnwdPosMin_Over180.Val
          PA_KeSMSw4sRecoveryMDSecRwLtStHdrstFrwdBkwdPos_160_Val: accessed-parameter=KeSMSw4sRecoveryMDSecRwLtStHdrstFrwdBkwdPos_160.Val
          PA_KeSMSw4sRecoveryMDSecRwLtStHdrstFrwdBkwdPos_165_Val: accessed-parameter=KeSMSw4sRecoveryMDSecRwLtStHdrstFrwdBkwdPos_165.Val
          PA_KeSMSw4sRecoveryMDSecRwLtStHdrstFrwdBkwdPos_170_Val: accessed-parameter=KeSMSw4sRecoveryMDSecRwLtStHdrstFrwdBkwdPos_170.Val
          PA_KeSMSw4sRecoveryMDSecRwLtStHdrstFrwdBkwdPos_175_Val: accessed-parameter=KeSMSw4sRecoveryMDSecRwLtStHdrstFrwdBkwdPos_175.Val
          PA_KeSMSw4sRecoveryMDSecRwLtStHdrstFrwdBkwdPos_180_Val: accessed-parameter=KeSMSw4sRecoveryMDSecRwLtStHdrstFrwdBkwdPos_180.Val
          PA_KeSMSw4sRecoveryMDSecRwLtStHdrstFrwdBkwdPos_Below160_Val: accessed-parameter=KeSMSw4sRecoveryMDSecRwLtStHdrstFrwdBkwdPos_Below160.Val
          PA_KeSMSw4sRecoveryMDSecRwLtStHdrstFrwdBkwdPos_Over180_Val: accessed-parameter=KeSMSw4sRecoveryMDSecRwLtStHdrstFrwdBkwdPos_Over180.Val
          PA_KeSMSw4sRecoveryMDSecRwLtStHdrstFrwdBkwdPosMax_160_Val: accessed-parameter=KeSMSw4sRecoveryMDSecRwLtStHdrstFrwdBkwdPosMax_160.Val
          PA_KeSMSw4sRecoveryMDSecRwLtStHdrstFrwdBkwdPosMax_165_Val: accessed-parameter=KeSMSw4sRecoveryMDSecRwLtStHdrstFrwdBkwdPosMax_165.Val
          PA_KeSMSw4sRecoveryMDSecRwLtStHdrstFrwdBkwdPosMax_170_Val: accessed-parameter=KeSMSw4sRecoveryMDSecRwLtStHdrstFrwdBkwdPosMax_170.Val
          PA_KeSMSw4sRecoveryMDSecRwLtStHdrstFrwdBkwdPosMax_175_Val: accessed-parameter=KeSMSw4sRecoveryMDSecRwLtStHdrstFrwdBkwdPosMax_175.Val
          PA_KeSMSw4sRecoveryMDSecRwLtStHdrstFrwdBkwdPosMax_180_Val: accessed-parameter=KeSMSw4sRecoveryMDSecRwLtStHdrstFrwdBkwdPosMax_180.Val
          PA_KeSMSw4sRecoveryMDSecRwLtStHdrstFrwdBkwdPosMax_Below160_Val: accessed-parameter=KeSMSw4sRecoveryMDSecRwLtStHdrstFrwdBkwdPosMax_Below160.Val
          PA_KeSMSw4sRecoveryMDSecRwLtStHdrstFrwdBkwdPosMax_Over180_Val: accessed-parameter=KeSMSw4sRecoveryMDSecRwLtStHdrstFrwdBkwdPosMax_Over180.Val
          PA_KeSMSw4sRecoveryMDSecRwLtStHdrstFrwdBkwdPosMin_160_Val: accessed-parameter=KeSMSw4sRecoveryMDSecRwLtStHdrstFrwdBkwdPosMin_160.Val
          PA_KeSMSw4sRecoveryMDSecRwLtStHdrstFrwdBkwdPosMin_165_Val: accessed-parameter=KeSMSw4sRecoveryMDSecRwLtStHdrstFrwdBkwdPosMin_165.Val
          PA_KeSMSw4sRecoveryMDSecRwLtStHdrstFrwdBkwdPosMin_170_Val: accessed-parameter=KeSMSw4sRecoveryMDSecRwLtStHdrstFrwdBkwdPosMin_170.Val
          PA_KeSMSw4sRecoveryMDSecRwLtStHdrstFrwdBkwdPosMin_175_Val: accessed-parameter=KeSMSw4sRecoveryMDSecRwLtStHdrstFrwdBkwdPosMin_175.Val
          PA_KeSMSw4sRecoveryMDSecRwLtStHdrstFrwdBkwdPosMin_180_Val: accessed-parameter=KeSMSw4sRecoveryMDSecRwLtStHdrstFrwdBkwdPosMin_180.Val
          PA_KeSMSw4sRecoveryMDSecRwLtStHdrstFrwdBkwdPosMin_Below160_Val: accessed-parameter=KeSMSw4sRecoveryMDSecRwLtStHdrstFrwdBkwdPosMin_Below160.Val
          PA_KeSMSw4sRecoveryMDSecRwLtStHdrstFrwdBkwdPosMin_Over180_Val: accessed-parameter=KeSMSw4sRecoveryMDSecRwLtStHdrstFrwdBkwdPosMin_Over180.Val
          PA_KeSMSw4sVIPMDSecRwLtStHdrstFrwdBkwdPos_160_Val: accessed-parameter=KeSMSw4sVIPMDSecRwLtStHdrstFrwdBkwdPos_160.Val
          PA_KeSMSw4sVIPMDSecRwLtStHdrstFrwdBkwdPos_165_Val: accessed-parameter=KeSMSw4sVIPMDSecRwLtStHdrstFrwdBkwdPos_165.Val
          PA_KeSMSw4sVIPMDSecRwLtStHdrstFrwdBkwdPos_170_Val: accessed-parameter=KeSMSw4sVIPMDSecRwLtStHdrstFrwdBkwdPos_170.Val
          PA_KeSMSw4sVIPMDSecRwLtStHdrstFrwdBkwdPos_175_Val: accessed-parameter=KeSMSw4sVIPMDSecRwLtStHdrstFrwdBkwdPos_175.Val
          PA_KeSMSw4sVIPMDSecRwLtStHdrstFrwdBkwdPos_180_Val: accessed-parameter=KeSMSw4sVIPMDSecRwLtStHdrstFrwdBkwdPos_180.Val
          PA_KeSMSw4sVIPMDSecRwLtStHdrstFrwdBkwdPos_Below160_Val: accessed-parameter=KeSMSw4sVIPMDSecRwLtStHdrstFrwdBkwdPos_Below160.Val
          PA_KeSMSw4sVIPMDSecRwLtStHdrstFrwdBkwdPos_Over180_Val: accessed-parameter=KeSMSw4sVIPMDSecRwLtStHdrstFrwdBkwdPos_Over180.Val
          PA_KeSMSw4sVIPMDSecRwLtStHdrstFrwdBkwdPosMax_160_Val: accessed-parameter=KeSMSw4sVIPMDSecRwLtStHdrstFrwdBkwdPosMax_160.Val
          PA_KeSMSw4sVIPMDSecRwLtStHdrstFrwdBkwdPosMax_165_Val: accessed-parameter=KeSMSw4sVIPMDSecRwLtStHdrstFrwdBkwdPosMax_165.Val
          PA_KeSMSw4sVIPMDSecRwLtStHdrstFrwdBkwdPosMax_170_Val: accessed-parameter=KeSMSw4sVIPMDSecRwLtStHdrstFrwdBkwdPosMax_170.Val
          PA_KeSMSw4sVIPMDSecRwLtStHdrstFrwdBkwdPosMax_175_Val: accessed-parameter=KeSMSw4sVIPMDSecRwLtStHdrstFrwdBkwdPosMax_175.Val
          PA_KeSMSw4sVIPMDSecRwLtStHdrstFrwdBkwdPosMax_180_Val: accessed-parameter=KeSMSw4sVIPMDSecRwLtStHdrstFrwdBkwdPosMax_180.Val
          PA_KeSMSw4sVIPMDSecRwLtStHdrstFrwdBkwdPosMax_Below160_Val: accessed-parameter=KeSMSw4sVIPMDSecRwLtStHdrstFrwdBkwdPosMax_Below160.Val
          PA_KeSMSw4sVIPMDSecRwLtStHdrstFrwdBkwdPosMax_Over180_Val: accessed-parameter=KeSMSw4sVIPMDSecRwLtStHdrstFrwdBkwdPosMax_Over180.Val
          PA_KeSMSw4sVIPMDSecRwLtStHdrstFrwdBkwdPosMin_160_Val: accessed-parameter=KeSMSw4sVIPMDSecRwLtStHdrstFrwdBkwdPosMin_160.Val
          PA_KeSMSw4sVIPMDSecRwLtStHdrstFrwdBkwdPosMin_165_Val: accessed-parameter=KeSMSw4sVIPMDSecRwLtStHdrstFrwdBkwdPosMin_165.Val
          PA_KeSMSw4sVIPMDSecRwLtStHdrstFrwdBkwdPosMin_170_Val: accessed-parameter=KeSMSw4sVIPMDSecRwLtStHdrstFrwdBkwdPosMin_170.Val
          PA_KeSMSw4sVIPMDSecRwLtStHdrstFrwdBkwdPosMin_175_Val: accessed-parameter=KeSMSw4sVIPMDSecRwLtStHdrstFrwdBkwdPosMin_175.Val
          PA_KeSMSw4sVIPMDSecRwLtStHdrstFrwdBkwdPosMin_180_Val: accessed-parameter=KeSMSw4sVIPMDSecRwLtStHdrstFrwdBkwdPosMin_180.Val
          PA_KeSMSw4sVIPMDSecRwLtStHdrstFrwdBkwdPosMin_Below160_Val: accessed-parameter=KeSMSw4sVIPMDSecRwLtStHdrstFrwdBkwdPosMin_Below160.Val
          PA_KeSMSw4sVIPMDSecRwLtStHdrstFrwdBkwdPosMin_Over180_Val: accessed-parameter=KeSMSw4sVIPMDSecRwLtStHdrstFrwdBkwdPosMin_Over180.Val
  swc implementation SecRwLtStHdrstFwdBkwdTrgtPosSelc_Implementation: behavior=SecRwLtStHdrstFwdBkwdTrgtPosSelc_InternalBehavior
    code-descriptors:
      code Default: artifact-descriptors=autosar-engineering-object={short-label=Default, category=SWSRC}
package /PATAC/MSM/ModeAdjust/CalPortInterface
  13 x parameter interface:
    KeSMSw4SAcsMd21SecRwLtStHdrstFrwdBkwdPos
      parameter data prototype Val: sw-calibration-access=READ-WRITE, type=UInt16
    KeSMSw4SAcsMd21SecRwLtStHdrstFrwdBkwdPosMax
      parameter data prototype Val: sw-calibration-access=READ-WRITE, type=UInt16
    KeSMSw4SAcsMd21SecRwLtStHdrstFrwdBkwdPosMin
      parameter data prototype Val: sw-calibration-access=READ-WRITE, type=UInt16
    KeSMSw4SAcsMd22SecRwLtStHdrstFrwdBkwdPos
      parameter data prototype Val: sw-calibration-access=READ-WRITE, type=UInt16
    KeSMSw4SAcsMd22SecRwLtStHdrstFrwdBkwdPosMax
      parameter data prototype Val: sw-calibration-access=READ-WRITE, type=UInt16
    KeSMSw4SAcsMd22SecRwLtStHdrstFrwdBkwdPosMin
      parameter data prototype Val: sw-calibration-access=READ-WRITE, type=UInt16
    KeSMSw4SAcsMd25SecRwLtStHdrstFrwdBkwdPos
      parameter data prototype Val: sw-calibration-access=READ-WRITE, type=UInt16
    KeSMSw4SAcsMd25SecRwLtStHdrstFrwdBkwdPosMax
      parameter data prototype Val: sw-calibration-access=READ-WRITE, type=UInt16
    KeSMSw4SAcsMd25SecRwLtStHdrstFrwdBkwdPosMin
      parameter data prototype Val: sw-calibration-access=READ-WRITE, type=UInt16
    KeSMSw4SAcsMd26SecRwLtStHdrstFrwdBkwdPos
      parameter data prototype Val: sw-calibration-access=READ-WRITE, type=UInt16
    KeSMSw4SAcsMd26SecRwLtStHdrstFrwdBkwdPosMax
      parameter data prototype Val: sw-calibration-access=READ-WRITE, type=UInt16
    KeSMSw4SAcsMd26SecRwLtStHdrstFrwdBkwdPosMin
      parameter data prototype Val: sw-calibration-access=READ-WRITE, type=UInt16
    Pos
      parameter data prototype Val: sw-calibration-access=READ-WRITE, type=UInt16
package /PATAC/MSM/ModeAdjust/DataType
  impl type TrgtPosCalibArray: category=ARRAY, sw-calibration-access=READ-ONLY, type-emitter=RTE  # 0:pos 1:max 2:min
    element Element: array-size=3, array-size-semantics=FIXED-SIZE, implementation-data-type=UInt16, invalid-value=0
package /PATAC/MSM/ModeAdjust/PortInterface
  client server interface SecRwLtStHdrstFwdBkwdTrgtPosSelc
    operation Cal
  sender receiver interface HeightIndex: invalidation-policy{data-element=Val, handle-invalid=DONT-INVALIDATE}
    data Val: type=UInt8  # 0：under 160 1：160 2：165 3：170 4：175 5：180 6：over 180
  sender receiver interface StNumFlg
    4 x data, all with type=Boolean:
      Is4s
      Is6s
      Is6s7s
      Is7s
    invalidation-policys:
      data-element=Is7s, handle-invalid=DONT-INVALIDATE
      data-element=Is6s, handle-invalid=DONT-INVALIDATE
      data-element=Is4s, handle-invalid=DONT-INVALIDATE
      data-element=Is6s7s, handle-invalid=DONT-INVALIDATE
  sender receiver interface TrgtPosCalibArray: invalidation-policy{data-element=TrgtPosArray, handle-invalid=DONT-INVALIDATE}
    data TrgtPosArray: type=TrgtPosCalibArray  # 0:Pos 1:Max 2:Min
